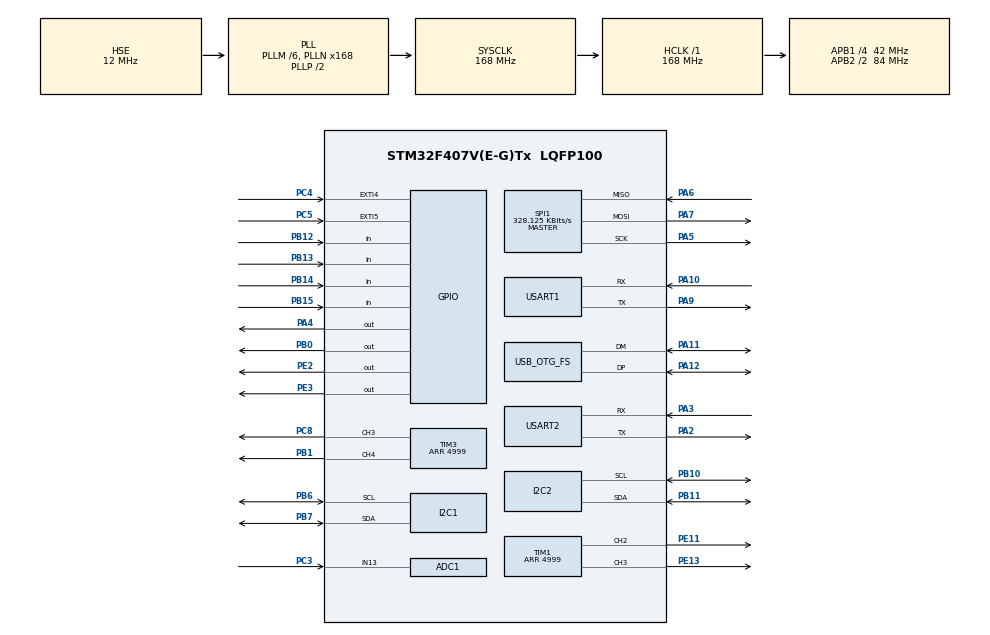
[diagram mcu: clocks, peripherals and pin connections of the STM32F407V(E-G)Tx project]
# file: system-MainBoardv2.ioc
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ADC1.Channel-0\#ChannelRegularConversion=ADC_CHANNEL_13
ADC1.NbrOfConversionFlag=1
ADC1.Rank-0\#ChannelRegularConversion=1
ADC1.SamplingTime-0\#ChannelRegularConversion=ADC_SAMPLETIME_3CYCLES
ADC1.master=1
Dma.Request0=SPI1_TX
Dma.Request1=SPI1_RX
Dma.Request2=USART1_RX
Dma.Request3=USART1_TX
Dma.SPI1_RX.1.Direction=DMA_PERIPH_TO_MEMORY
Dma.SPI1_RX.1.FIFOMode=DMA_FIFOMODE_DISABLE
Dma.SPI1_RX.1.Instance=DMA2_Stream0
Dma.SPI1_RX.1.MemDataAlignment=DMA_MDATAALIGN_BYTE
Dma.SPI1_RX.1.MemInc=DMA_MINC_ENABLE
Dma.SPI1_RX.1.Mode=DMA_NORMAL
Dma.SPI1_RX.1.PeriphDataAlignment=DMA_PDATAALIGN_BYTE
Dma.SPI1_RX.1.PeriphInc=DMA_PINC_DISABLE
Dma.SPI1_RX.1.Priority=DMA_PRIORITY_VERY_HIGH
Dma.SPI1_TX.0.Direction=DMA_MEMORY_TO_PERIPH
Dma.SPI1_TX.0.FIFOMode=DMA_FIFOMODE_DISABLE
Dma.SPI1_TX.0.Instance=DMA2_Stream3
Dma.SPI1_TX.0.MemDataAlignment=DMA_MDATAALIGN_BYTE
Dma.SPI1_TX.0.MemInc=DMA_MINC_ENABLE
Dma.SPI1_TX.0.Mode=DMA_NORMAL
Dma.SPI1_TX.0.PeriphDataAlignment=DMA_PDATAALIGN_BYTE
Dma.SPI1_TX.0.PeriphInc=DMA_PINC_DISABLE
Dma.SPI1_TX.0.Priority=DMA_PRIORITY_HIGH
Dma.USART1_RX.2.Direction=DMA_PERIPH_TO_MEMORY
Dma.USART1_RX.2.FIFOMode=DMA_FIFOMODE_DISABLE
Dma.USART1_RX.2.Instance=DMA2_Stream2
Dma.USART1_RX.2.MemDataAlignment=DMA_MDATAALIGN_BYTE
Dma.USART1_RX.2.MemInc=DMA_MINC_ENABLE
Dma.USART1_RX.2.Mode=DMA_NORMAL
Dma.USART1_RX.2.PeriphDataAlignment=DMA_PDATAALIGN_BYTE
Dma.USART1_RX.2.PeriphInc=DMA_PINC_DISABLE
Dma.USART1_RX.2.Priority=DMA_PRIORITY_LOW
Dma.USART1_TX.3.Direction=DMA_MEMORY_TO_PERIPH
Dma.USART1_TX.3.FIFOMode=DMA_FIFOMODE_DISABLE
Dma.USART1_TX.3.Instance=DMA2_Stream7
Dma.USART1_TX.3.MemDataAlignment=DMA_MDATAALIGN_BYTE
Dma.USART1_TX.3.MemInc=DMA_MINC_ENABLE
Dma.USART1_TX.3.Mode=DMA_NORMAL
Dma.USART1_TX.3.PeriphDataAlignment=DMA_PDATAALIGN_BYTE
Dma.USART1_TX.3.PeriphInc=DMA_PINC_DISABLE
Dma.USART1_TX.3.Priority=DMA_PRIORITY_LOW
Mcu.Family=STM32F4
Mcu.Name=STM32F407V(E-G)Tx
Mcu.Package=LQFP100
NVIC.DMA2_Stream0_IRQn=true\:0\:0\:false\:false\:true\:false\:true\:true
NVIC.DMA2_Stream2_IRQn=true\:0\:0\:false\:false\:true\:false\:true\:true
NVIC.DMA2_Stream3_IRQn=true\:0\:0\:false\:false\:true\:false\:true\:true
NVIC.DMA2_Stream7_IRQn=true\:0\:0\:false\:false\:true\:false\:true\:true
NVIC.EXTI4_IRQn=true\:5\:0\:true\:false\:true\:true\:true\:true
NVIC.EXTI9_5_IRQn=true\:5\:0\:true\:false\:true\:true\:true\:true
NVIC.PriorityGroup=NVIC_PRIORITYGROUP_4
PA10.Mode=Asynchronous
PA10.Signal=USART1_RX
PA11.Mode=Device_Only
PA11.Signal=USB_OTG_FS_DM
PA12.Mode=Device_Only
PA12.Signal=USB_OTG_FS_DP
PA13.Mode=Serial_Wire
PA13.Signal=SYS_JTMS-SWDIO
PA14.Mode=Serial_Wire
PA14.Signal=SYS_JTCK-SWCLK
PA2.Mode=Asynchronous
PA2.Signal=USART2_TX
PA3.Mode=Asynchronous
PA3.Signal=USART2_RX
PA4.GPIO_PuPd=GPIO_PULLUP
PA4.GPIO_Speed=GPIO_SPEED_FREQ_HIGH
PA4.PinState=GPIO_PIN_SET
PA4.Signal=GPIO_Output
PA5.Mode=Full_Duplex_Master
PA5.Signal=SPI1_SCK
PA6.Mode=Full_Duplex_Master
PA6.Signal=SPI1_MISO
PA7.Mode=Full_Duplex_Master
PA7.Signal=SPI1_MOSI
PA9.Mode=Asynchronous
PA9.Signal=USART1_TX
PB0.GPIO_ModeDefaultOutputPP=GPIO_MODE_OUTPUT_PP
PB0.GPIO_PuPd=GPIO_PULLUP
PB0.GPIO_Speed=GPIO_SPEED_FREQ_HIGH
PB0.PinState=GPIO_PIN_SET
PB0.Signal=GPIO_Output
PB1.Signal=S_TIM3_CH4
PB10.Mode=I2C
PB10.Signal=I2C2_SCL
PB11.Mode=I2C
PB11.Signal=I2C2_SDA
PB12.GPIO_PuPd=GPIO_PULLUP
PB12.Signal=GPIO_Input
PB13.GPIO_PuPd=GPIO_PULLUP
PB13.Signal=GPIO_Input
PB14.Signal=GPIO_Input
PB15.Signal=GPIO_Input
PB6.Mode=I2C
PB6.Signal=I2C1_SCL
PB7.Mode=I2C
PB7.Signal=I2C1_SDA
PC3.Signal=ADCx_IN13
PC4.GPIO_ModeDefaultEXTI=GPIO_MODE_IT_FALLING
PC4.Signal=GPXTI4
PC5.GPIO_ModeDefaultEXTI=GPIO_MODE_IT_FALLING
PC5.Signal=GPXTI5
PC8.Signal=S_TIM3_CH3
PE11.Signal=S_TIM1_CH2
PE13.Signal=S_TIM1_CH3
PE2.GPIO_PuPd=GPIO_PULLUP
PE2.PinState=GPIO_PIN_SET
PE2.Signal=GPIO_Output
PE3.GPIO_PuPd=GPIO_PULLUP
PE3.PinState=GPIO_PIN_SET
PE3.Signal=GPIO_Output
PH0-OSC_IN.Mode=HSE-External-Oscillator
PH0-OSC_IN.Signal=RCC_OSC_IN
PH1-OSC_OUT.Mode=HSE-External-Oscillator
PH1-OSC_OUT.Signal=RCC_OSC_OUT
ProjectManager.HeapSize=0x200
ProjectManager.StackSize=0x400
ProjectManager.TargetToolchain=MDK-ARM V5.32
RCC.48MHZClocksFreq_Value=48000000
RCC.AHBFreq_Value=168000000
RCC.APB1CLKDivider=RCC_HCLK_DIV4
RCC.APB1Freq_Value=42000000
RCC.APB1TimFreq_Value=84000000
RCC.APB2CLKDivider=RCC_HCLK_DIV2
RCC.APB2Freq_Value=84000000
RCC.APB2TimFreq_Value=168000000
RCC.CortexFreq_Value=168000000
RCC.HCLKFreq_Value=168000000
RCC.HSE_VALUE=12000000
RCC.HSI_VALUE=16000000
RCC.LSE_VALUE=32768
RCC.PLLM=6
RCC.PLLN=168
RCC.PLLQ=7
RCC.SYSCLKFreq_VALUE=168000000
RCC.SYSCLKSource=RCC_SYSCLKSOURCE_PLLCLK
RCC.VCOOutputFreq_Value=336000000
SH.ADCx_IN13.0=ADC1_IN13,IN13
SH.S_TIM1_CH2.0=TIM1_CH2,PWM Generation2 CH2
SH.S_TIM1_CH3.0=TIM1_CH3,PWM Generation3 CH3
SH.S_TIM3_CH3.0=TIM3_CH3,PWM Generation3 CH3
SH.S_TIM3_CH4.0=TIM3_CH4,PWM Generation4 CH4
SPI1.BaudRatePrescaler=SPI_BAUDRATEPRESCALER_256
SPI1.CLKPhase=SPI_PHASE_2EDGE
SPI1.CLKPolarity=SPI_POLARITY_HIGH
SPI1.CalculateBaudRate=328.125 KBits/s
SPI1.Direction=SPI_DIRECTION_2LINES
SPI1.Mode=SPI_MODE_MASTER
SPI1.VirtualType=VM_MASTER
TIM1.Channel-PWM\ Generation2\ CH2=TIM_CHANNEL_2
TIM1.Channel-PWM\ Generation3\ CH3=TIM_CHANNEL_3
TIM1.Period=4999
TIM3.Channel-PWM\ Generation3\ CH3=TIM_CHANNEL_3
TIM3.Channel-PWM\ Generation4\ CH4=TIM_CHANNEL_4
TIM3.Period=4999
USART1.VirtualMode=VM_ASYNC
USART2.VirtualMode=VM_ASYNC
USB_OTG_FS.VirtualMode=Device_Only
VP_CRC_VS_CRC.Mode=CRC_Activate
board=custom

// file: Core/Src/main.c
/* USER CODE BEGIN Header */
/**
  ******************************************************************************
  * @file           : main.c
  * @brief          : Main program body
  ******************************************************************************
  * @attention
  *
  * Copyright (c) 2025 STMicroelectronics.
  * All rights reserved.
  *
  * This software is licensed under terms that can be found in the LICENSE file
  * in the root directory of this software component.
  * If no LICENSE file comes with this software, it is provided AS-IS.
  *
  ******************************************************************************
  */
/* USER CODE END Header */
#include "main.h"
#include "adc.h"
#include "crc.h"
#include "dma.h"
#include "i2c.h"
#include "spi.h"
#include "tim.h"
#include "usart.h"
#include "usb_otg.h"
#include "gpio.h"

/* USER CODE BEGIN Includes */
#include "BMI088driver.h"
/* USER CODE END Includes */

void SystemClock_Config(void);

/* USER CODE BEGIN 0 */
fp32 gyro[3], accel[3], temp;
/* USER CODE END 0 */

int main(void)
{

  /* MCU Configuration--------------------------------------------------------*/

  /* Reset of all peripherals, Initializes the Flash interface and the Systick. */
  HAL_Init();

  /* Configure the system clock */
  SystemClock_Config();

  /* Initialize all configured peripherals */
  MX_GPIO_Init();
  MX_DMA_Init();
  MX_SPI1_Init();
  MX_USART1_UART_Init();
  MX_USART2_UART_Init();
  MX_I2C2_Init();
  MX_TIM1_Init();
  MX_TIM3_Init();
  MX_USB_OTG_FS_PCD_Init();
  MX_ADC1_Init();
  MX_CRC_Init();
  MX_I2C1_Init();
  /* USER CODE BEGIN 2 */
    while(BMI088_init())
    {
        ;
    }
  /* USER CODE END 2 */

  /* Infinite loop */
  while (1)
  {

    /* USER CODE BEGIN 3 */
        BMI088_read(gyro, accel, &temp);
        HAL_Delay(10);
  }
  /* USER CODE END 3 */
}

void SystemClock_Config(void)
{
  RCC_OscInitTypeDef RCC_OscInitStruct = {0};
  RCC_ClkInitTypeDef RCC_ClkInitStruct = {0};

  /** Configure the main internal regulator output voltage
  */
  __HAL_RCC_PWR_CLK_ENABLE();
  __HAL_PWR_VOLTAGESCALING_CONFIG(PWR_REGULATOR_VOLTAGE_SCALE1);

  /** Initializes the RCC Oscillators according to the specified parameters
  * in the RCC_OscInitTypeDef structure.
  */
  RCC_OscInitStruct.OscillatorType = RCC_OSCILLATORTYPE_HSE;
  RCC_OscInitStruct.HSEState = RCC_HSE_ON;
  RCC_OscInitStruct.PLL.PLLState = RCC_PLL_ON;
  RCC_OscInitStruct.PLL.PLLSource = RCC_PLLSOURCE_HSE;
  RCC_OscInitStruct.PLL.PLLM = 6;
  RCC_OscInitStruct.PLL.PLLN = 168;
  RCC_OscInitStruct.PLL.PLLP = RCC_PLLP_DIV2;
  RCC_OscInitStruct.PLL.PLLQ = 7;
  if (HAL_RCC_OscConfig(&RCC_OscInitStruct) != HAL_OK)
  {
    Error_Handler();
  }

  /** Initializes the CPU, AHB and APB buses clocks
  */
  RCC_ClkInitStruct.ClockType = RCC_CLOCKTYPE_HCLK|RCC_CLOCKTYPE_SYSCLK
                              |RCC_CLOCKTYPE_PCLK1|RCC_CLOCKTYPE_PCLK2;
  RCC_ClkInitStruct.SYSCLKSource = RCC_SYSCLKSOURCE_PLLCLK;
  RCC_ClkInitStruct.AHBCLKDivider = RCC_SYSCLK_DIV1;
  RCC_ClkInitStruct.APB1CLKDivider = RCC_HCLK_DIV4;
  RCC_ClkInitStruct.APB2CLKDivider = RCC_HCLK_DIV2;

  if (HAL_RCC_ClockConfig(&RCC_ClkInitStruct, FLASH_LATENCY_5) != HAL_OK)
  {
    Error_Handler();
  }
}

void Error_Handler(void)
{
  __disable_irq();
  while (1)
  {
  }
}
